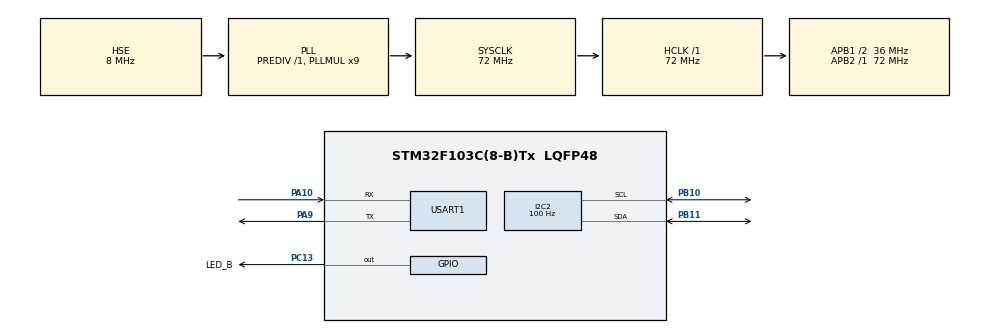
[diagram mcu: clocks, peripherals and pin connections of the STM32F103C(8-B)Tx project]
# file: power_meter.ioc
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Dma.Request0=USART1_TX
Dma.Request1=USART1_RX
Dma.USART1_RX.1.Direction=DMA_PERIPH_TO_MEMORY
Dma.USART1_RX.1.Instance=DMA1_Channel5
Dma.USART1_RX.1.MemDataAlignment=DMA_MDATAALIGN_BYTE
Dma.USART1_RX.1.MemInc=DMA_MINC_ENABLE
Dma.USART1_RX.1.Mode=DMA_NORMAL
Dma.USART1_RX.1.PeriphDataAlignment=DMA_PDATAALIGN_BYTE
Dma.USART1_RX.1.PeriphInc=DMA_PINC_DISABLE
Dma.USART1_RX.1.Priority=DMA_PRIORITY_HIGH
Dma.USART1_TX.0.Direction=DMA_MEMORY_TO_PERIPH
Dma.USART1_TX.0.Instance=DMA1_Channel4
Dma.USART1_TX.0.MemDataAlignment=DMA_MDATAALIGN_BYTE
Dma.USART1_TX.0.MemInc=DMA_MINC_ENABLE
Dma.USART1_TX.0.Mode=DMA_NORMAL
Dma.USART1_TX.0.PeriphDataAlignment=DMA_PDATAALIGN_BYTE
Dma.USART1_TX.0.PeriphInc=DMA_PINC_DISABLE
Dma.USART1_TX.0.Priority=DMA_PRIORITY_HIGH
FREERTOS.Tasks01=defaultTask,0,128,StartDefaultTask,Default,NULL,Dynamic,NULL,NULL;led,-3,128,LED_TASK,As weak,NULL,Dynamic,NULL,NULL;uart_debug,-3,128,UART_DEBUG_TASK,As weak,NULL,Dynamic,NULL,NULL;get_power,-3,128,GET_POWER_TASK,As weak,NULL,Dynamic,NULL,NULL
FREERTOS.configUSE_NEWLIB_REENTRANT=1
I2C2.ClockSpeed=100
Mcu.Family=STM32F1
Mcu.Name=STM32F103C(8-B)Tx
Mcu.Package=LQFP48
NVIC.DMA1_Channel4_IRQn=true\:5\:0\:false\:false\:true\:true\:false\:true\:true
NVIC.DMA1_Channel5_IRQn=true\:5\:0\:false\:false\:true\:true\:false\:true\:true
NVIC.PriorityGroup=NVIC_PRIORITYGROUP_4
NVIC.TIM4_IRQn=true\:15\:0\:false\:false\:true\:false\:false\:true\:true
NVIC.TimeBase=TIM4_IRQn
NVIC.TimeBaseIP=TIM4
NVIC.USART1_IRQn=true\:5\:0\:false\:false\:true\:true\:true\:true\:true
PA10.Mode=Asynchronous
PA10.Signal=USART1_RX
PA13.Mode=Serial_Wire
PA13.Signal=SYS_JTMS-SWDIO
PA14.Mode=Serial_Wire
PA14.Signal=SYS_JTCK-SWCLK
PA9.Mode=Asynchronous
PA9.Signal=USART1_TX
PB10.Mode=I2C
PB10.Signal=I2C2_SCL
PB11.Mode=I2C
PB11.Signal=I2C2_SDA
PC13-TAMPER-RTC.GPIO_Label=LED_B
PC13-TAMPER-RTC.Signal=GPIO_Output
PD0-OSC_IN.Mode=HSE-External-Oscillator
PD0-OSC_IN.Signal=RCC_OSC_IN
PD1-OSC_OUT.Mode=HSE-External-Oscillator
PD1-OSC_OUT.Signal=RCC_OSC_OUT
ProjectManager.HeapSize=0x200
ProjectManager.StackSize=0x400
ProjectManager.TargetToolchain=STM32CubeIDE
RCC.AHBFreq_Value=72000000
RCC.APB1CLKDivider=RCC_HCLK_DIV2
RCC.APB1Freq_Value=36000000
RCC.APB1TimFreq_Value=72000000
RCC.APB2Freq_Value=72000000
RCC.APB2TimFreq_Value=72000000
RCC.HCLKFreq_Value=72000000
RCC.PLLMUL=RCC_PLL_MUL9
RCC.PLLSourceVirtual=RCC_PLLSOURCE_HSE
RCC.SYSCLKFreq_VALUE=72000000
RCC.SYSCLKSource=RCC_SYSCLKSOURCE_PLLCLK
RCC.USBFreq_Value=72000000
USART1.VirtualMode=VM_ASYNC
VP_FREERTOS_VS_CMSIS_V1.Mode=CMSIS_V1
VP_SYS_VS_tim4.Mode=TIM4
board=custom

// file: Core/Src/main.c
/* USER CODE BEGIN Header */
/**
  ******************************************************************************
  * @file           : main.c
  * @brief          : Main program body
  ******************************************************************************
  * @attention
  *
  * Copyright (c) 2025 STMicroelectronics.
  * All rights reserved.
  *
  * This software is licensed under terms that can be found in the LICENSE file
  * in the root directory of this software component.
  * If no LICENSE file comes with this software, it is provided AS-IS.
  *
  ******************************************************************************
  */
/* USER CODE END Header */
#include "main.h"
#include "cmsis_os.h"
#include "dma.h"
#include "i2c.h"
#include "usart.h"
#include "gpio.h"

/* USER CODE BEGIN Includes */
#include "LED_TASK.h"
#include "bsp_ina226.h"
#include "GET_POWER_TASK.h"
/* USER CODE END Includes */

/* USER CODE BEGIN PV */
float fVoltage = 0 ;
float fCurrent = 0 ;
float fPower = 0 ;

/* USER CODE END PV */

void SystemClock_Config(void);
void MX_FREERTOS_Init(void);

int main(void)
{

  /* MCU Configuration--------------------------------------------------------*/

  /* Reset of all peripherals, Initializes the Flash interface and the Systick. */
  HAL_Init();

  /* Configure the system clock */
  SystemClock_Config();

  /* Initialize all configured peripherals */
  MX_GPIO_Init();
  MX_DMA_Init();
  MX_USART1_UART_Init();
  MX_I2C2_Init();

  /* Call init function for freertos objects (in cmsis_os2.c) */
  MX_FREERTOS_Init();

  /* Start scheduler */
  osKernelStart();

  /* We should never get here as control is now taken by the scheduler */

  /* Infinite loop */
  while (1)
  {

  }
}

void SystemClock_Config(void)
{
  RCC_OscInitTypeDef RCC_OscInitStruct = {0};
  RCC_ClkInitTypeDef RCC_ClkInitStruct = {0};

  /** Initializes the RCC Oscillators according to the specified parameters
  * in the RCC_OscInitTypeDef structure.
  */
  RCC_OscInitStruct.OscillatorType = RCC_OSCILLATORTYPE_HSE;
  RCC_OscInitStruct.HSEState = RCC_HSE_ON;
  RCC_OscInitStruct.HSEPredivValue = RCC_HSE_PREDIV_DIV1;
  RCC_OscInitStruct.HSIState = RCC_HSI_ON;
  RCC_OscInitStruct.PLL.PLLState = RCC_PLL_ON;
  RCC_OscInitStruct.PLL.PLLSource = RCC_PLLSOURCE_HSE;
  RCC_OscInitStruct.PLL.PLLMUL = RCC_PLL_MUL9;
  if (HAL_RCC_OscConfig(&RCC_OscInitStruct) != HAL_OK)
  {
    Error_Handler();
  }

  /** Initializes the CPU, AHB and APB buses clocks
  */
  RCC_ClkInitStruct.ClockType = RCC_CLOCKTYPE_HCLK|RCC_CLOCKTYPE_SYSCLK
                              |RCC_CLOCKTYPE_PCLK1|RCC_CLOCKTYPE_PCLK2;
  RCC_ClkInitStruct.SYSCLKSource = RCC_SYSCLKSOURCE_PLLCLK;
  RCC_ClkInitStruct.AHBCLKDivider = RCC_SYSCLK_DIV1;
  RCC_ClkInitStruct.APB1CLKDivider = RCC_HCLK_DIV2;
  RCC_ClkInitStruct.APB2CLKDivider = RCC_HCLK_DIV1;

  if (HAL_RCC_ClockConfig(&RCC_ClkInitStruct, FLASH_LATENCY_2) != HAL_OK)
  {
    Error_Handler();
  }
}

void HAL_TIM_PeriodElapsedCallback(TIM_HandleTypeDef *htim)
{
  if (htim->Instance == TIM4) {
    HAL_IncTick();
  }
}

void Error_Handler(void)
{
  __disable_irq();
  while (1)
  {
  }
}

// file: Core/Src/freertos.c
/* USER CODE BEGIN Header */
/**
  ******************************************************************************
  * File Name          : freertos.c
  * Description        : Code for freertos applications
  ******************************************************************************
  * @attention
  *
  * Copyright (c) 2025 STMicroelectronics.
  * All rights reserved.
  *
  * This software is licensed under terms that can be found in the LICENSE file
  * in the root directory of this software component.
  * If no LICENSE file comes with this software, it is provided AS-IS.
  *
  ******************************************************************************
  */
/* USER CODE END Header */

#include "FreeRTOS.h"
#include "task.h"
#include "main.h"
#include "cmsis_os.h"

osThreadId defaultTaskHandle;
osThreadId ledHandle;
osThreadId uart_debugHandle;
osThreadId get_powerHandle;

void StartDefaultTask(void const * argument);
void LED_TASK(void const * argument);
void UART_DEBUG_TASK(void const * argument);
void GET_POWER_TASK(void const * argument);

void MX_FREERTOS_Init(void); /* (MISRA C 2004 rule 8.1) */

/* GetIdleTaskMemory prototype (linked to static allocation support) */
void vApplicationGetIdleTaskMemory( StaticTask_t **ppxIdleTaskTCBBuffer, StackType_t **ppxIdleTaskStackBuffer, uint32_t *pulIdleTaskStackSize );

/* USER CODE BEGIN GET_IDLE_TASK_MEMORY */
static StaticTask_t xIdleTaskTCBBuffer;
static StackType_t xIdleStack[configMINIMAL_STACK_SIZE];

void vApplicationGetIdleTaskMemory( StaticTask_t **ppxIdleTaskTCBBuffer, StackType_t **ppxIdleTaskStackBuffer, uint32_t *pulIdleTaskStackSize )
{
  *ppxIdleTaskTCBBuffer = &xIdleTaskTCBBuffer;
  *ppxIdleTaskStackBuffer = &xIdleStack[0];
  *pulIdleTaskStackSize = configMINIMAL_STACK_SIZE;
  /* place for user code */
}
/* USER CODE END GET_IDLE_TASK_MEMORY */

void MX_FREERTOS_Init(void) {

  /* Create the thread(s) */
  /* definition and creation of defaultTask */
  osThreadDef(defaultTask, StartDefaultTask, osPriorityNormal, 0, 128);
  defaultTaskHandle = osThreadCreate(osThread(defaultTask), NULL);

  /* definition and creation of led */
  osThreadDef(led, LED_TASK, osPriorityIdle, 0, 128);
  ledHandle = osThreadCreate(osThread(led), NULL);

  /* definition and creation of uart_debug */
  osThreadDef(uart_debug, UART_DEBUG_TASK, osPriorityIdle, 0, 128);
  uart_debugHandle = osThreadCreate(osThread(uart_debug), NULL);

  /* definition and creation of get_power */
  osThreadDef(get_power, GET_POWER_TASK, osPriorityIdle, 0, 128);
  get_powerHandle = osThreadCreate(osThread(get_power), NULL);

}

void StartDefaultTask(void const * argument)
{
  for(;;)
  {
    osDelay(1);
  }
}

__weak void LED_TASK(void const * argument)
{
  for(;;)
  {
    osDelay(1);
  }
}

__weak void UART_DEBUG_TASK(void const * argument)
{
  for(;;)
  {
    osDelay(1);
  }
}

__weak void GET_POWER_TASK(void const * argument)
{
  for(;;)
  {
    osDelay(1);
  }
}
